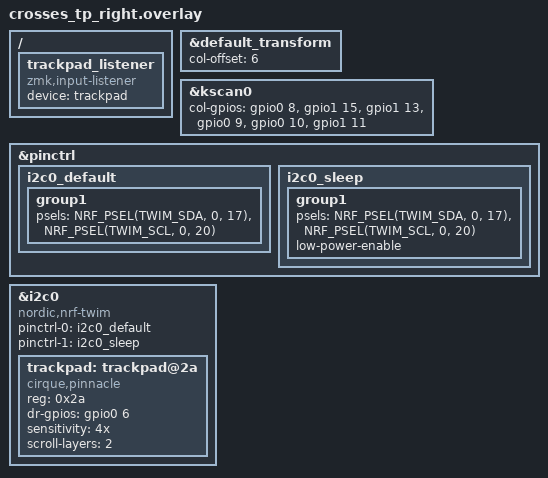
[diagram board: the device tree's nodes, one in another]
/*
 * Copyright (c) 2020 ZMK Contributors
 *
 * SPDX-License-Identifier: MIT
 */

#include "crosses_tp.dtsi"

&default_transform {
    col-offset = <6>;
};

&kscan0 {
	col-gpios
		= <&gpio0 8 (GPIO_ACTIVE_HIGH | GPIO_PULL_DOWN)>
		, <&gpio1 15 (GPIO_ACTIVE_HIGH | GPIO_PULL_DOWN)>
		, <&gpio1 13 (GPIO_ACTIVE_HIGH | GPIO_PULL_DOWN)>
		, <&gpio0 9 (GPIO_ACTIVE_HIGH | GPIO_PULL_DOWN)>
		, <&gpio0 10  (GPIO_ACTIVE_HIGH | GPIO_PULL_DOWN)>
		, <&gpio1 11 (GPIO_ACTIVE_HIGH | GPIO_PULL_DOWN)>

		;
};


// trackpad bus
&pinctrl {
    i2c0_default: i2c0_default {
        group1 {
            psels = <NRF_PSEL(TWIM_SDA, 0, 17)>,
                    <NRF_PSEL(TWIM_SCL, 0, 20)>;
        };
    };

    i2c0_sleep: i2c0_sleep {
        group1 {
            psels = <NRF_PSEL(TWIM_SDA, 0, 17)>,
                    <NRF_PSEL(TWIM_SCL, 0, 20)>;
            low-power-enable;
        };
    };
};

&i2c0 {
    status = "okay";
    compatible = "nordic,nrf-twim";
    pinctrl-0 = <&i2c0_default>;
    pinctrl-1 = <&i2c0_sleep>;
    pinctrl-names = "default", "sleep";

    trackpad: trackpad@2a {
        compatible = "cirque,pinnacle";
        reg = <0x2a>;
        dr-gpios = <&gpio0 6 (GPIO_ACTIVE_HIGH)>;
        sensitivity = "4x";
        scroll-layers = <2>;
    };
};


/ {
    trackpad_listener {
        compatible = "zmk,input-listener";
        device = <&trackpad>;
    };
};
